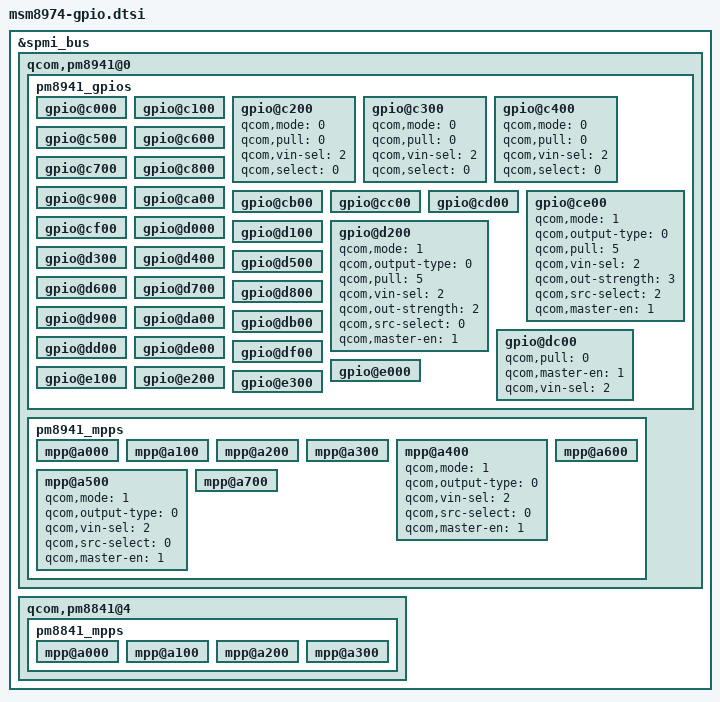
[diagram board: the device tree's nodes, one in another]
/* Copyright (c) 2012, The Linux Foundation. All rights reserved.
 *
 * This program is free software; you can redistribute it and/or modify
 * it under the terms of the GNU General Public License version 2 and
 * only version 2 as published by the Free Software Foundation.
 *
 * This program is distributed in the hope that it will be useful,
 * but WITHOUT ANY WARRANTY; without even the implied warranty of
 * MERCHANTABILITY or FITNESS FOR A PARTICULAR PURPOSE.  See the
 * GNU General Public License for more details.
 */

&spmi_bus {

	qcom,pm8941@0 {

		pm8941_gpios: pm8941_gpios {

			gpio@c000 {
			};

			gpio@c100 {
			};

			gpio@c200 {
				qcom,mode = <0>;
				qcom,pull = <0>;
				qcom,vin-sel = <2>;
				qcom,select = <0>;
			};

			gpio@c300 {
				qcom,mode = <0>;
				qcom,pull = <0>;
				qcom,vin-sel = <2>;
				qcom,select = <0>;
			};

			gpio@c400 {
				qcom,mode = <0>;
				qcom,pull = <0>;
				qcom,vin-sel = <2>;
				qcom,select = <0>;
			};

			gpio@c500 {
			};

			gpio@c600 {
			};

			gpio@c700 {
			};

			gpio@c800 {
			};

			gpio@c900 {
			};

			gpio@ca00 {
			};

			gpio@cb00 {
			};

			gpio@cc00 {
			};

			gpio@cd00 {
			};

			gpio@ce00 {
				qcom,mode = <1>;
				qcom,output-type = <0>;
				qcom,pull = <5>;
				qcom,vin-sel = <2>;
				qcom,out-strength = <3>;
				qcom,src-select = <2>;
				qcom,master-en = <1>;
			};

			gpio@cf00 {
			};

			gpio@d000 {
			};

			gpio@d100 {
			};

			gpio@d200 {
				qcom,mode = <1>;		/* QPNP_PIN_MODE_DIG_OUT */
				qcom,output-type = <0>;		/* QPNP_PIN_OUT_BUF_CMOS */
				qcom,pull = <5>;		/* QPNP_PIN_PULL_NO */
				qcom,vin-sel = <2>;		/* QPNP_PIN_VIN2 */
				qcom,out-strength = <2>;	/* QPNP_PIN_OUT_STRENGTH_MED */
				qcom,src-select = <0>;		/* QPNP_PIN_SEL_FUNC_CONSTANT */
				qcom,master-en = <1>;
			};

			gpio@d300 {
			};

			gpio@d400 {
			};

			gpio@d500 {
			};

			gpio@d600 {
			};

			gpio@d700 {
			};

			gpio@d800 {
			};

			gpio@d900 {
			};

			gpio@da00 {
			};

			gpio@db00 {
			};

			gpio@dc00 {
				qcom,pull = <0>; /* set to default pull */
				qcom,master-en = <1>;
				qcom,vin-sel = <2>; /* select 1.8 V source */
			};

			gpio@dd00 {
			};

			gpio@de00 {
			};

			gpio@df00 {
			};

			gpio@e000 {
			};

			gpio@e100 {
			};

			gpio@e200 {
			};

			gpio@e300 {
			};
		};

		pm8941_mpps: pm8941_mpps {

			mpp@a000 {
			};

			mpp@a100 {
			};

			mpp@a200 {
			};

			mpp@a300 {
			};

			mpp@a400 {
				/* SPI_ETH config */
				qcom,mode = <1>; /* DIG_OUT */
				qcom,output-type = <0>; /* CMOS */
				qcom,vin-sel = <2>; /* PM8941_S3 1.8V > 1.6V */
				qcom,src-select = <0>; /* CONSTANT */
				qcom,master-en = <1>; /* ENABLE MPP */
			};

			mpp@a500 {
				/* SPI_ETH_RST config */
				qcom,mode = <1>; /* DIG_OUT */
				qcom,output-type = <0>; /* CMOS */
				qcom,vin-sel = <2>; /* PM8941_S3 1.8V > 1.6V */
				qcom,src-select = <0>; /* CONSTANT */
				qcom,master-en = <1>; /* ENABLE MPP */
			};

			mpp@a600 {
			};

			mpp@a700 {
			};
		};
	};

	qcom,pm8841@4 {

		pm8841_mpps: pm8841_mpps {

			mpp@a000 {
			};

			mpp@a100 {
			};

			mpp@a200 {
			};

			mpp@a300 {
			};
		};
	};
};
